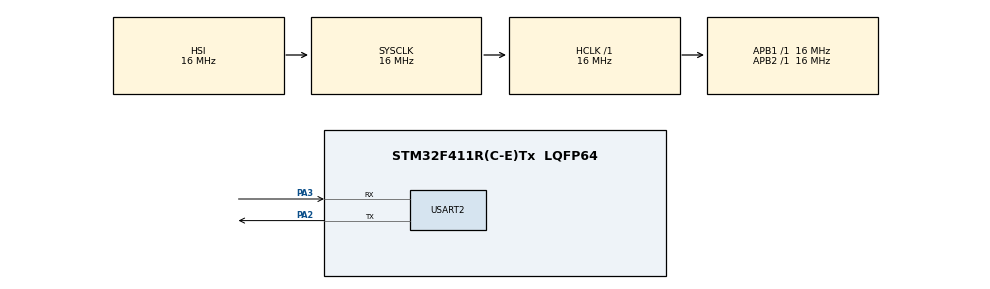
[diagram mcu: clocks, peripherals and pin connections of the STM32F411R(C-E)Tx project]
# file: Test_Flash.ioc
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Mcu.Family=STM32F4
Mcu.Name=STM32F411R(C-E)Tx
Mcu.Package=LQFP64
NVIC.PriorityGroup=NVIC_PRIORITYGROUP_4
PA2.Mode=Asynchronous
PA2.Signal=USART2_TX
PA3.Mode=Asynchronous
PA3.Signal=USART2_RX
ProjectManager.HeapSize=0x200
ProjectManager.StackSize=0x400
ProjectManager.TargetToolchain=SW4STM32
RCC.AHBFreq_Value=16000000
RCC.APB1Freq_Value=16000000
RCC.APB2Freq_Value=16000000
RCC.CortexFreq_Value=16000000
RCC.HSE_VALUE=25000000
RCC.HSI_VALUE=16000000
RCC.LSE_VALUE=32768
RCC.SYSCLKFreq_VALUE=16000000
RCC.VCOOutputFreq_Value=192000000
USART2.VirtualMode=VM_ASYNC
board=custom

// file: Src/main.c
/**
  ******************************************************************************
  * @file           : main.c
  * @brief          : Main program body
  ******************************************************************************
  ** This notice applies to any and all portions of this file
  * that are not between comment pairs USER CODE BEGIN and
  * USER CODE END. Other portions of this file, whether
  * inserted by the user or by software development tools
  * are owned by their respective copyright owners.
  *
  * COPYRIGHT(c) 2019 STMicroelectronics
  *
  * Redistribution and use in source and binary forms, with or without modification,
  * are permitted provided that the following conditions are met:
  *   1. Redistributions of source code must retain the above copyright notice,
  *      this list of conditions and the following disclaimer.
  *   2. Redistributions in binary form must reproduce the above copyright notice,
  *      this list of conditions and the following disclaimer in the documentation
  *      and/or other materials provided with the distribution.
  *   3. Neither the name of STMicroelectronics nor the names of its contributors
  *      may be used to endorse or promote products derived from this software
  *      without specific prior written permission.
  *
  * THIS SOFTWARE IS PROVIDED BY THE COPYRIGHT HOLDERS AND CONTRIBUTORS "AS IS"
  * AND ANY EXPRESS OR IMPLIED WARRANTIES, INCLUDING, BUT NOT LIMITED TO, THE
  * IMPLIED WARRANTIES OF MERCHANTABILITY AND FITNESS FOR A PARTICULAR PURPOSE ARE
  * DISCLAIMED. IN NO EVENT SHALL THE COPYRIGHT HOLDER OR CONTRIBUTORS BE LIABLE
  * FOR ANY DIRECT, INDIRECT, INCIDENTAL, SPECIAL, EXEMPLARY, OR CONSEQUENTIAL
  * DAMAGES (INCLUDING, BUT NOT LIMITED TO, PROCUREMENT OF SUBSTITUTE GOODS OR
  * SERVICES; LOSS OF USE, DATA, OR PROFITS; OR BUSINESS INTERRUPTION) HOWEVER
  * CAUSED AND ON ANY THEORY OF LIABILITY, WHETHER IN CONTRACT, STRICT LIABILITY,
  * OR TORT (INCLUDING NEGLIGENCE OR OTHERWISE) ARISING IN ANY WAY OUT OF THE USE
  * OF THIS SOFTWARE, EVEN IF ADVISED OF THE POSSIBILITY OF SUCH DAMAGE.
  *
  ******************************************************************************
  */
#include "main.h"
#include "stm32f4xx_hal.h"
#include "stm32f4xx_hal_flash.h"
#include "string.h"

UART_HandleTypeDef huart2;

/* USER CODE BEGIN PV */
/* Private variables ---------------------------------------------------------*/

/* USER CODE END PV */

void SystemClock_Config(void);
static void MX_GPIO_Init(void);
static void MX_USART2_UART_Init(void);

/* USER CODE BEGIN PFP */
/* Private function prototypes -----------------------------------------------*/

/* USER CODE END PFP */

/* USER CODE BEGIN 0 */
//__attribute__((__section__(".user_data"))) const uint8_t userConfig[128];
const volatile uint8_t *userConfig=(const volatile uint8_t *)0x08060000;

typedef struct{
	uint8_t ver;

	uint16_t min1;
	uint16_t min2;

	uint16_t max1;
	uint16_t max2;
}data_stc;

/* USER CODE END 0 */

int main(void)
{

  /* MCU Configuration----------------------------------------------------------*/

  /* Reset of all peripherals, Initializes the Flash interface and the Systick. */
  HAL_Init();

  /* Configure the system clock */
  SystemClock_Config();

  /* Initialize all configured peripherals */
  MX_GPIO_Init();
  MX_USART2_UART_Init();

  /* Infinite loop */
  /* USER CODE BEGIN WHILE */

  data_stc data={.ver=10, .max1=100, .max2=200, .min1=10, .min2=20};

  uint8_t ver;
  uint16_t flag = 0;

  //UNUSED METHODS TO ACQUIRE DATA FROM MEMORY
  //buff = *((uint8_t*) &userConfig[0]);
  //memcpy(&txt_, &userConfig[0], 8);

  //reading in the first address of the memory
  ver = userConfig[0];
  if(ver == data.ver){						//if the byte is equal to our ver, we can read the next saved data
	  flag = 1;
  }
  else{										//else we have to write others data

	  HAL_FLASH_Unlock();					//unlocking the flash memory

	  __HAL_FLASH_CLEAR_FLAG(FLASH_FLAG_EOP | FLASH_FLAG_OPERR | FLASH_FLAG_WRPERR | FLASH_FLAG_PGAERR | FLASH_FLAG_PGSERR );

	  FLASH_Erase_Sector(FLASH_SECTOR_7, VOLTAGE_RANGE_3);

	  int error = HAL_FLASH_Program(TYPEPROGRAM_BYTE, &userConfig[0], 10);		//write byte

	  uint8_t h = data.max1 / 256;
	  uint8_t l = data.max1 % 256;

	  error = HAL_FLASH_Program(TYPEPROGRAM_BYTE, &userConfig[1], h);
	  error = HAL_FLASH_Program(TYPEPROGRAM_BYTE, &userConfig[2], l);

	  HAL_FLASH_Lock();						//unlocking the flash memory
  }

  while (1)
  {

  /* USER CODE END WHILE */

  /* USER CODE BEGIN 3 */
	  uint8_t txt[10];
	  txt[0] = userConfig[0];
	  txt[1] = userConfig[1];
	  txt[2] = userConfig[2];
	  //sprintf(txt, "%d\t%d\r\n", error, &userConfig[0]);
	  char text[4];
	  sprintf(text, "%d\t%d\t-", flag, ver);
	  HAL_UART_Transmit(&huart2, (uint8_t*)text, strlen(text), 10);
	  //HAL_UART_Transmit(&huart2, (uint8_t*)txt_, 1, 10);
	  HAL_UART_Transmit(&huart2, (uint8_t*)txt, 10, 10);
	  HAL_UART_Transmit(&huart2, (uint8_t*)"\r\n", 2, 10);

  }
  /* USER CODE END 3 */

}

void SystemClock_Config(void)
{

  RCC_OscInitTypeDef RCC_OscInitStruct;
  RCC_ClkInitTypeDef RCC_ClkInitStruct;

    /**Configure the main internal regulator output voltage
    */
  __HAL_RCC_PWR_CLK_ENABLE();

  __HAL_PWR_VOLTAGESCALING_CONFIG(PWR_REGULATOR_VOLTAGE_SCALE1);

    /**Initializes the CPU, AHB and APB busses clocks
    */
  RCC_OscInitStruct.OscillatorType = RCC_OSCILLATORTYPE_HSI;
  RCC_OscInitStruct.HSIState = RCC_HSI_ON;
  RCC_OscInitStruct.HSICalibrationValue = 16;
  RCC_OscInitStruct.PLL.PLLState = RCC_PLL_NONE;
  if (HAL_RCC_OscConfig(&RCC_OscInitStruct) != HAL_OK)
  {
    _Error_Handler(__FILE__, __LINE__);
  }

    /**Initializes the CPU, AHB and APB busses clocks
    */
  RCC_ClkInitStruct.ClockType = RCC_CLOCKTYPE_HCLK|RCC_CLOCKTYPE_SYSCLK
                              |RCC_CLOCKTYPE_PCLK1|RCC_CLOCKTYPE_PCLK2;
  RCC_ClkInitStruct.SYSCLKSource = RCC_SYSCLKSOURCE_HSI;
  RCC_ClkInitStruct.AHBCLKDivider = RCC_SYSCLK_DIV1;
  RCC_ClkInitStruct.APB1CLKDivider = RCC_HCLK_DIV1;
  RCC_ClkInitStruct.APB2CLKDivider = RCC_HCLK_DIV1;

  if (HAL_RCC_ClockConfig(&RCC_ClkInitStruct, FLASH_LATENCY_0) != HAL_OK)
  {
    _Error_Handler(__FILE__, __LINE__);
  }

    /**Configure the Systick interrupt time
    */
  HAL_SYSTICK_Config(HAL_RCC_GetHCLKFreq()/1000);

    /**Configure the Systick
    */
  HAL_SYSTICK_CLKSourceConfig(SYSTICK_CLKSOURCE_HCLK);

  /* SysTick_IRQn interrupt configuration */
  HAL_NVIC_SetPriority(SysTick_IRQn, 0, 0);
}

/* USART2 init function */
static void MX_USART2_UART_Init(void)
{

  huart2.Instance = USART2;
  huart2.Init.BaudRate = 115200;
  huart2.Init.WordLength = UART_WORDLENGTH_8B;
  huart2.Init.StopBits = UART_STOPBITS_1;
  huart2.Init.Parity = UART_PARITY_NONE;
  huart2.Init.Mode = UART_MODE_TX_RX;
  huart2.Init.HwFlowCtl = UART_HWCONTROL_NONE;
  huart2.Init.OverSampling = UART_OVERSAMPLING_16;
  if (HAL_UART_Init(&huart2) != HAL_OK)
  {
    _Error_Handler(__FILE__, __LINE__);
  }

}

/** Pinout Configuration
*/
static void MX_GPIO_Init(void)
{

  /* GPIO Ports Clock Enable */
  __HAL_RCC_GPIOA_CLK_ENABLE();

}

void _Error_Handler(char *file, int line)
{
  while(1)
  {
  }
}

/************************ (C) COPYRIGHT STMicroelectronics *****END OF FILE****/
